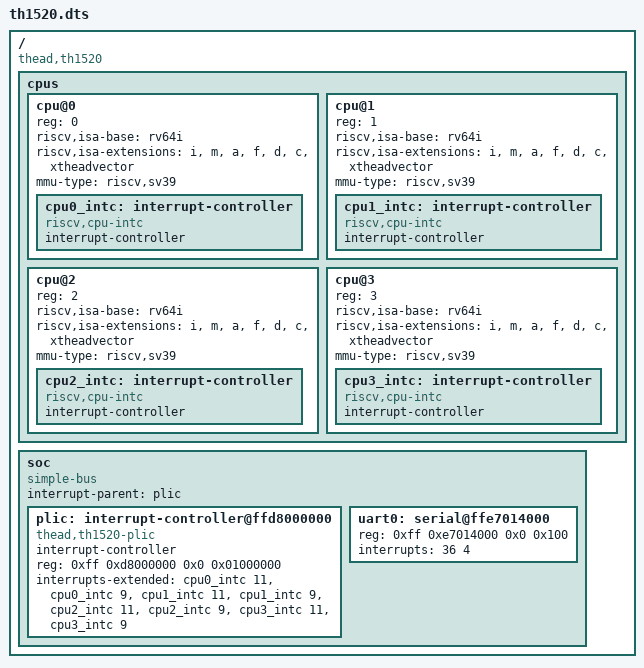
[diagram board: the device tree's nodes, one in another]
/dts-v1/;

/*
 * A hand-written device tree MODELED ON the T-Head TH1520 (the SoC in Scaleway's Elastic Metal
 * RV1 and the Lichee Pi 4A), NOT a dump from a machine and not a copy of any upstream file. Prep
 * for milestone 89 (Scaleway EM-RV1: a second RISC-V implementation, rented), 2026-09-25 (UTC).
 * The values below were read from `arch/riscv/boot/dts/thead/th1520.dtsi` in torvalds/linux at
 * commit cbbddb6b08cc, fetched 2026-11-01 (UTC), and only the properties the tests in
 * `riscv64_th1520.rs` read are kept. The RV1's own tree comes from its firmware and is read off
 * the machine in the first rented hour; this fixture stands in for it until then.
 *
 * What makes it different from both machines this tree already boots:
 *
 *   plic       `thead,th1520-plic`, `thead,c900-plic`, and neither `sifive,plic-1.0.0` nor
 *              `riscv,plic0`. At 0xff_d800_0000, 40 bits up, far past the 256 GiB the Sv39 direct
 *              map reaches. `#interrupt-cells = <2>` (number and trigger), not QEMU's 1.
 *   contexts   M then S per hart, so hart h's S context is 2h+1, QEMU's layout.
 *   serial     uart0 at 0xff_e701_4000, interrupt 36.
 *   cpus       four C910s, Sv39; no sstc, svpbmt or zicbom, and `xtheadvector` (RVV 0.7.1), which
 *              this tree does not know and must ignore.
 *
 * Rebuild with:
 *     dtc -I dts -O dtb -o crates/machine_discovery/tests/fixtures/th1520.dtb \
 *         crates/machine_discovery/tests/fixtures/th1520.dts
 */

/ {
	compatible = "thead,th1520";
	#address-cells = <2>;
	#size-cells = <2>;

	cpus {
		#address-cells = <1>;
		#size-cells = <0>;

		cpu@0 {
			device_type = "cpu";
			reg = <0>;
			riscv,isa-base = "rv64i";
			riscv,isa-extensions = "i", "m", "a", "f", "d", "c", "xtheadvector";
			mmu-type = "riscv,sv39";

			cpu0_intc: interrupt-controller {
				compatible = "riscv,cpu-intc";
				interrupt-controller;
				#interrupt-cells = <1>;
			};
		};

		cpu@1 {
			device_type = "cpu";
			reg = <1>;
			riscv,isa-base = "rv64i";
			riscv,isa-extensions = "i", "m", "a", "f", "d", "c", "xtheadvector";
			mmu-type = "riscv,sv39";

			cpu1_intc: interrupt-controller {
				compatible = "riscv,cpu-intc";
				interrupt-controller;
				#interrupt-cells = <1>;
			};
		};

		cpu@2 {
			device_type = "cpu";
			reg = <2>;
			riscv,isa-base = "rv64i";
			riscv,isa-extensions = "i", "m", "a", "f", "d", "c", "xtheadvector";
			mmu-type = "riscv,sv39";

			cpu2_intc: interrupt-controller {
				compatible = "riscv,cpu-intc";
				interrupt-controller;
				#interrupt-cells = <1>;
			};
		};

		cpu@3 {
			device_type = "cpu";
			reg = <3>;
			riscv,isa-base = "rv64i";
			riscv,isa-extensions = "i", "m", "a", "f", "d", "c", "xtheadvector";
			mmu-type = "riscv,sv39";

			cpu3_intc: interrupt-controller {
				compatible = "riscv,cpu-intc";
				interrupt-controller;
				#interrupt-cells = <1>;
			};
		};
	};

	soc {
		compatible = "simple-bus";
		interrupt-parent = <&plic>;
		#address-cells = <2>;
		#size-cells = <2>;
		ranges;

		plic: interrupt-controller@ffd8000000 {
			#interrupt-cells = <2>;
			interrupt-controller;
			reg = <0xff 0xd8000000 0x0 0x01000000>;
			compatible = "thead,th1520-plic", "thead,c900-plic";
			interrupts-extended = <&cpu0_intc 11>, <&cpu0_intc 9>,
					      <&cpu1_intc 11>, <&cpu1_intc 9>,
					      <&cpu2_intc 11>, <&cpu2_intc 9>,
					      <&cpu3_intc 11>, <&cpu3_intc 9>;
		};

		uart0: serial@ffe7014000 {
			reg = <0xff 0xe7014000 0x0 0x100>;
			interrupts = <36 4>;
		};
	};
};
